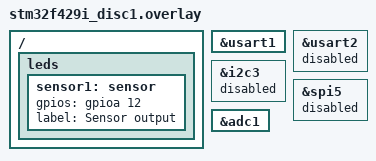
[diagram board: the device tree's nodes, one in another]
/ {
	leds {
		sensor1: sensor {
			gpios = <&gpioa 12 GPIO_ACTIVE_HIGH>;
			label = "Sensor output";
			status = "okay";
		};
	};
};

&usart1 {
	status = "okay";
};

&usart2 {
	status = "disabled";
};

&i2c3 {
	status = "disabled";
};

&spi5 {
	status = "disabled";
};

&adc1 {
	// pinctrl-0 = <&adc1_in0_pa0>;
	status = "okay";
};
